# MKL28T7_CORE0 register map
Vendor: Freescale Semiconductor, Inc.; Series: Kinetis_L; File version: 1.6
CPU: CM0PLUS r0p0, little endian, no MPU, no FPU, VTOR, 2 interrupt priority bits
Registers are 32-bit, read-write, reset 0x0 unless marked. A register's access mark holds for its fields unless they carry their own. Offsets are from the block's base; [hi:lo] are bit positions; 'fields as' and 'values as' point back to an identical list.

## CRC — Cyclic Redundancy Check
Base 0x40078000; register names take the prefix CRC_
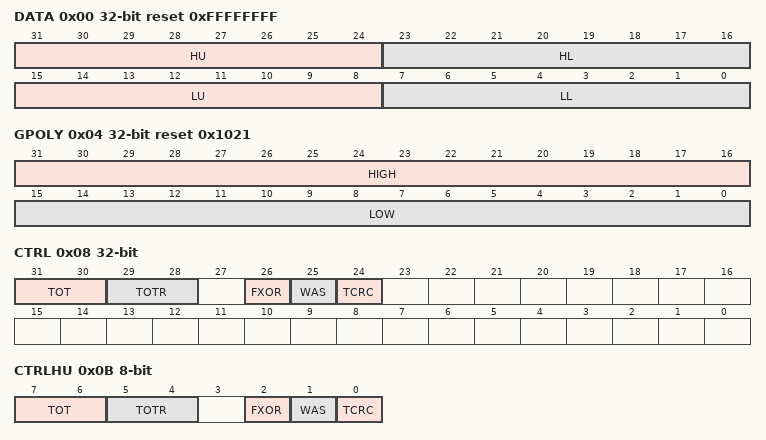
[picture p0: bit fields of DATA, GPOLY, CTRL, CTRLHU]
0x00 DATA reset 0xFFFFFFFF (CRC view) — CRC Data register
  [31:24] HU — CRC High Upper Byte
  [23:16] HL — CRC High Lower Byte
  [15:8] LU — CRC Low Upper Byte
  [7:0] LL — CRC Low Lower Byte
0x00 DATAL 16-bit reset 0xFFFF (CRC view) — CRC_DATAL register.
  [15:0] DATAL — DATAL stores the lower 16 bits of the 16/32 bit CRC
0x00 DATALL 8-bit reset 0xFF (CRC view) — CRC_DATALL register.
  [7:0] DATALL — CRCLL stores the first 8 bits of the 32 bit DATA
0x01 DATALU 8-bit reset 0xFF — CRC_DATALU register.
  [7:0] DATALU — DATALL stores the second 8 bits of the 32 bit CRC
0x02 DATAH 16-bit reset 0xFFFF (CRC view) — CRC_DATAH register.
  [15:0] DATAH — DATAH stores the high 16 bits of the 16/32 bit CRC
0x02 DATAHL 8-bit reset 0xFF (CRC view) — CRC_DATAHL register.
  [7:0] DATAHL — DATAHL stores the third 8 bits of the 32 bit CRC
0x03 DATAHU 8-bit reset 0xFF — CRC_DATAHU register.
  [7:0] DATAHU — DATAHU stores the fourth 8 bits of the 32 bit CRC
0x04 GPOLY reset 0x1021 (CRC view) — CRC Polynomial register
  [31:16] HIGH — High Polynominal Half-word
  [15:0] LOW — Low Polynominal Half-word
0x04 GPOLYL 16-bit reset 0xFFFF (CRC view) — CRC_GPOLYL register.
  [15:0] GPOLYL — POLYL stores the lower 16 bits of the 16/32 bit CRC polynomial value
0x04 GPOLYLL 8-bit reset 0xFF (CRC view) — CRC_GPOLYLL register.
  [7:0] GPOLYLL — POLYLL stores the first 8 bits of the 32 bit CRC
0x05 GPOLYLU 8-bit reset 0xFF — CRC_GPOLYLU register.
  [7:0] GPOLYLU — POLYLL stores the second 8 bits of the 32 bit CRC
0x06 GPOLYH 16-bit reset 0xFFFF (CRC view) — CRC_GPOLYH register.
  [15:0] GPOLYH — POLYH stores the high 16 bits of the 16/32 bit CRC polynomial value
0x06 GPOLYHL 8-bit reset 0xFF (CRC view) — CRC_GPOLYHL register.
  [7:0] GPOLYHL — POLYHL stores the third 8 bits of the 32 bit CRC
0x07 GPOLYHU 8-bit reset 0xFF — CRC_GPOLYHU register.
  [7:0] GPOLYHU — POLYHU stores the fourth 8 bits of the 32 bit CRC
0x08 CTRL — CRC Control register
  [31:30] TOT — Type Of Transpose For Writes
    0=No transposition; 1=Bits in bytes are transposed; bytes are not transposed; 2=Both bits in bytes and bytes are transposed; 3=Only bytes are transposed; no bits in a byte are transposed
  [29:28] TOTR — Type Of Transpose For Read
    values as TOT
  [26] FXOR — Complement Read Of CRC Data Register
    0=No XOR on reading; 1=Invert or complement the read value of the CRC Data register
  [25] WAS — Write CRC Data Register As Seed
    0=Writes to the CRC data register are data values; 1=Writes to the CRC data register are seed values
  [24] TCRC — Width of CRC protocol.
    0=16-bit CRC protocol; 1=32-bit CRC protocol
0x0B CTRLHU 8-bit — CRC_CTRLHU register.
  [7:6] TOT
    0=No Transposition; 1=Bits in bytes are transposed, bytes are not transposed; 2=Both bits in bytes and bytes are transposed; 3=Only bytes are transposed; no bits in a byte are transposed
  [5:4] TOTR
    values as TOT
  [2] FXOR
    0=No XOR on reading; 1=Invert or complement the read value of CRC data register
  [1] WAS
    0=Writes to CRC data register are data values; 1=Writes to CRC data reguster are seed values
  [0] TCRC
    0=16-bit CRC protocol; 1=32-bit CRC protocol

## PCC1
Base 0x400FA000
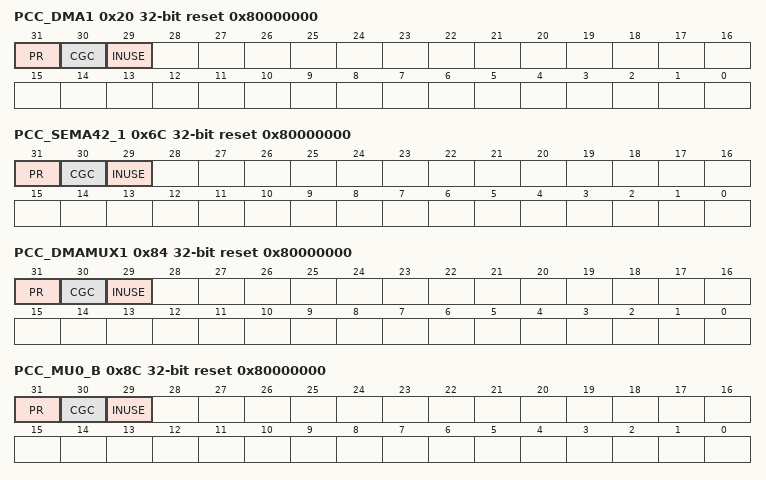
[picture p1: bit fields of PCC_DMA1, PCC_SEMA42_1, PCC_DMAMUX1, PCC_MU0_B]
0x20 PCC_DMA1 reset 0x80000000 — PCC CLKCFG Register
  [31] PR ro — Enable
    0=Peripheral is not present; 1=Peripheral is present
  [30] CGC — Clock Gate Control
    0=Clock disabled; 1=Clock enabled
  [29] INUSE ro — Clock Gate Control
    0=Another core is not using this peripheral; 1=Another core is using this peripheral. Software cannot modify the existing clocking configuration.
0x6C PCC_SEMA42_1 reset 0x80000000 — PCC CLKCFG Register
  fields as PCC_DMA1
0x84 PCC_DMAMUX1 reset 0x80000000 — PCC CLKCFG Register
  fields as PCC_DMA1
0x8C PCC_MU0_B reset 0x80000000 — PCC CLKCFG Register
  fields as PCC_DMA1
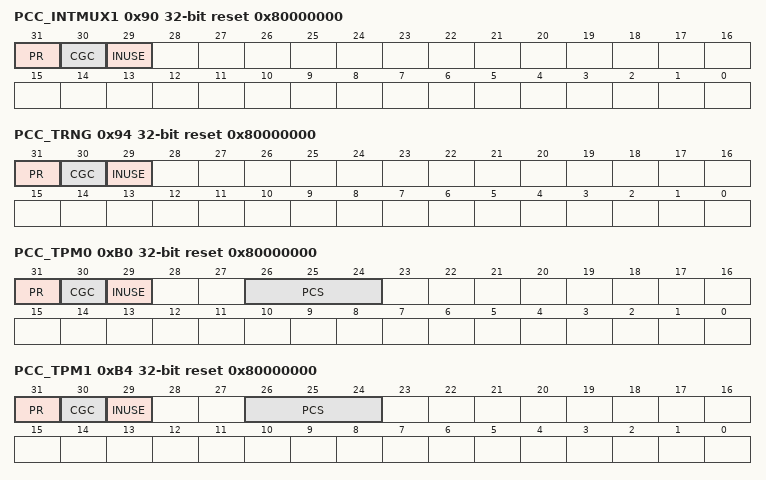
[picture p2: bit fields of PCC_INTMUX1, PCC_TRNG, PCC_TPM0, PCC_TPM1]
0x90 PCC_INTMUX1 reset 0x80000000 — PCC CLKCFG Register
  fields as PCC_DMA1
0x94 PCC_TRNG reset 0x80000000 — PCC CLKCFG Register
  fields as PCC_DMA1
0xB0 PCC_TPM0 reset 0x80000000 — PCC CLKCFG Register
  [31] PR ro — Enable
    0=Peripheral is not present; 1=Peripheral is present
  [30] CGC — Clock Gate Control
    0=Clock disabled; 1=Clock enabled
  [29] INUSE ro — Clock Gate Control
    values as PCC_DMA1.INUSE
  [26:24] PCS — Peripheral Clock Source Select
    0=Clock is off (or test clock is enabled); 1=OSCCLK - System Oscillator Bus Clock(scg_sosc_slow_clk); 2=SCGIRCLK - Slow IRC Clock(scg_sirc_slow_clk), (maximum is 8MHz); 3=SCGFIRCLK - Fast IRC Clock(scg_firc_slow_clk), (maximum is 48MHz); 6=SCGPCLK System PLL clock (scg_spll_slow_clk)
0xB4 PCC_TPM1 reset 0x80000000 — PCC CLKCFG Register
  fields as PCC_TPM0
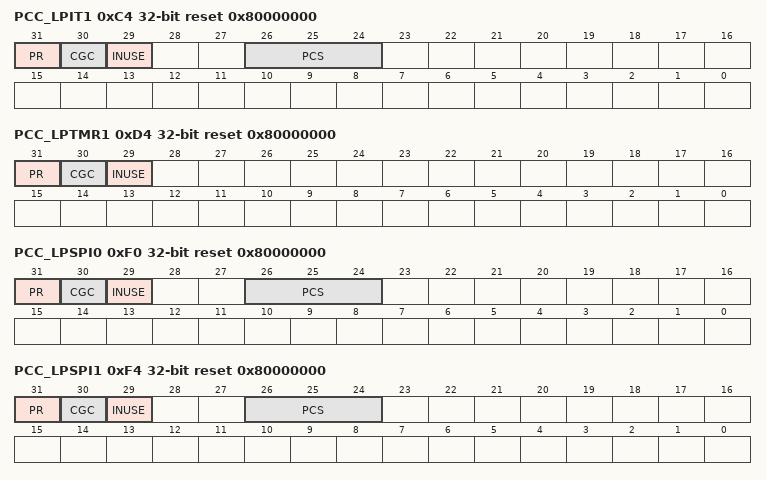
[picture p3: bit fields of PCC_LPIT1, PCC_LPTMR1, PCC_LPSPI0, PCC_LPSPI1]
0xC4 PCC_LPIT1 reset 0x80000000 — PCC CLKCFG Register
  fields as PCC_TPM0
0xD4 PCC_LPTMR1 reset 0x80000000 — PCC CLKCFG Register
  fields as PCC_DMA1
0xF0 PCC_LPSPI0 reset 0x80000000 — PCC CLKCFG Register
  fields as PCC_TPM0
0xF4 PCC_LPSPI1 reset 0x80000000 — PCC CLKCFG Register
  fields as PCC_TPM0
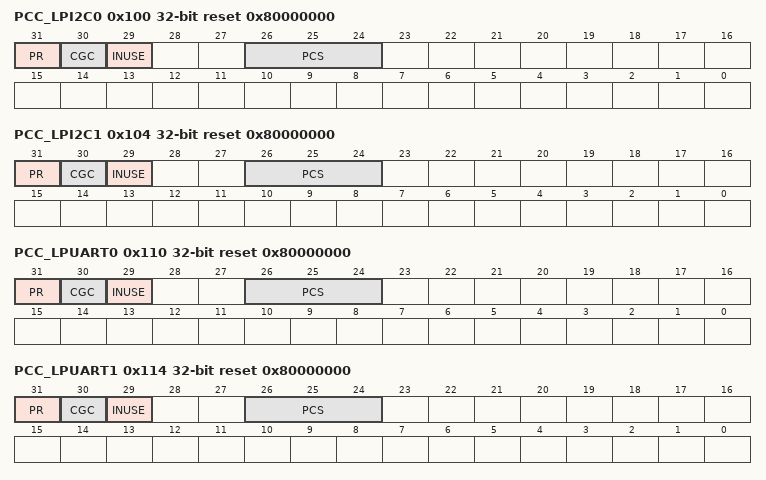
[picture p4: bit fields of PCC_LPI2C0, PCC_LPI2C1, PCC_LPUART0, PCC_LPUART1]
0x100 PCC_LPI2C0 reset 0x80000000 — PCC CLKCFG Register
  fields as PCC_TPM0
0x104 PCC_LPI2C1 reset 0x80000000 — PCC CLKCFG Register
  fields as PCC_TPM0
0x110 PCC_LPUART0 reset 0x80000000 — PCC CLKCFG Register
  fields as PCC_TPM0
0x114 PCC_LPUART1 reset 0x80000000 — PCC CLKCFG Register
  fields as PCC_TPM0
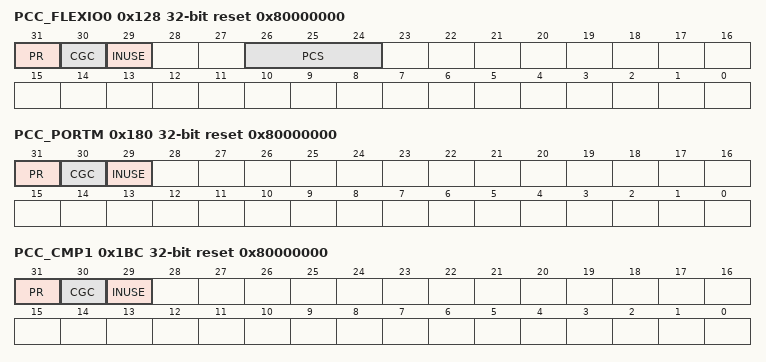
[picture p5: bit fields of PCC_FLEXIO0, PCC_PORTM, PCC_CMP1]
0x128 PCC_FLEXIO0 reset 0x80000000 — PCC CLKCFG Register
  fields as PCC_TPM0
0x180 PCC_PORTM reset 0x80000000 — PCC CLKCFG Register
  fields as PCC_DMA1
0x1BC PCC_CMP1 reset 0x80000000 — PCC CLKCFG Register
  fields as PCC_DMA1
